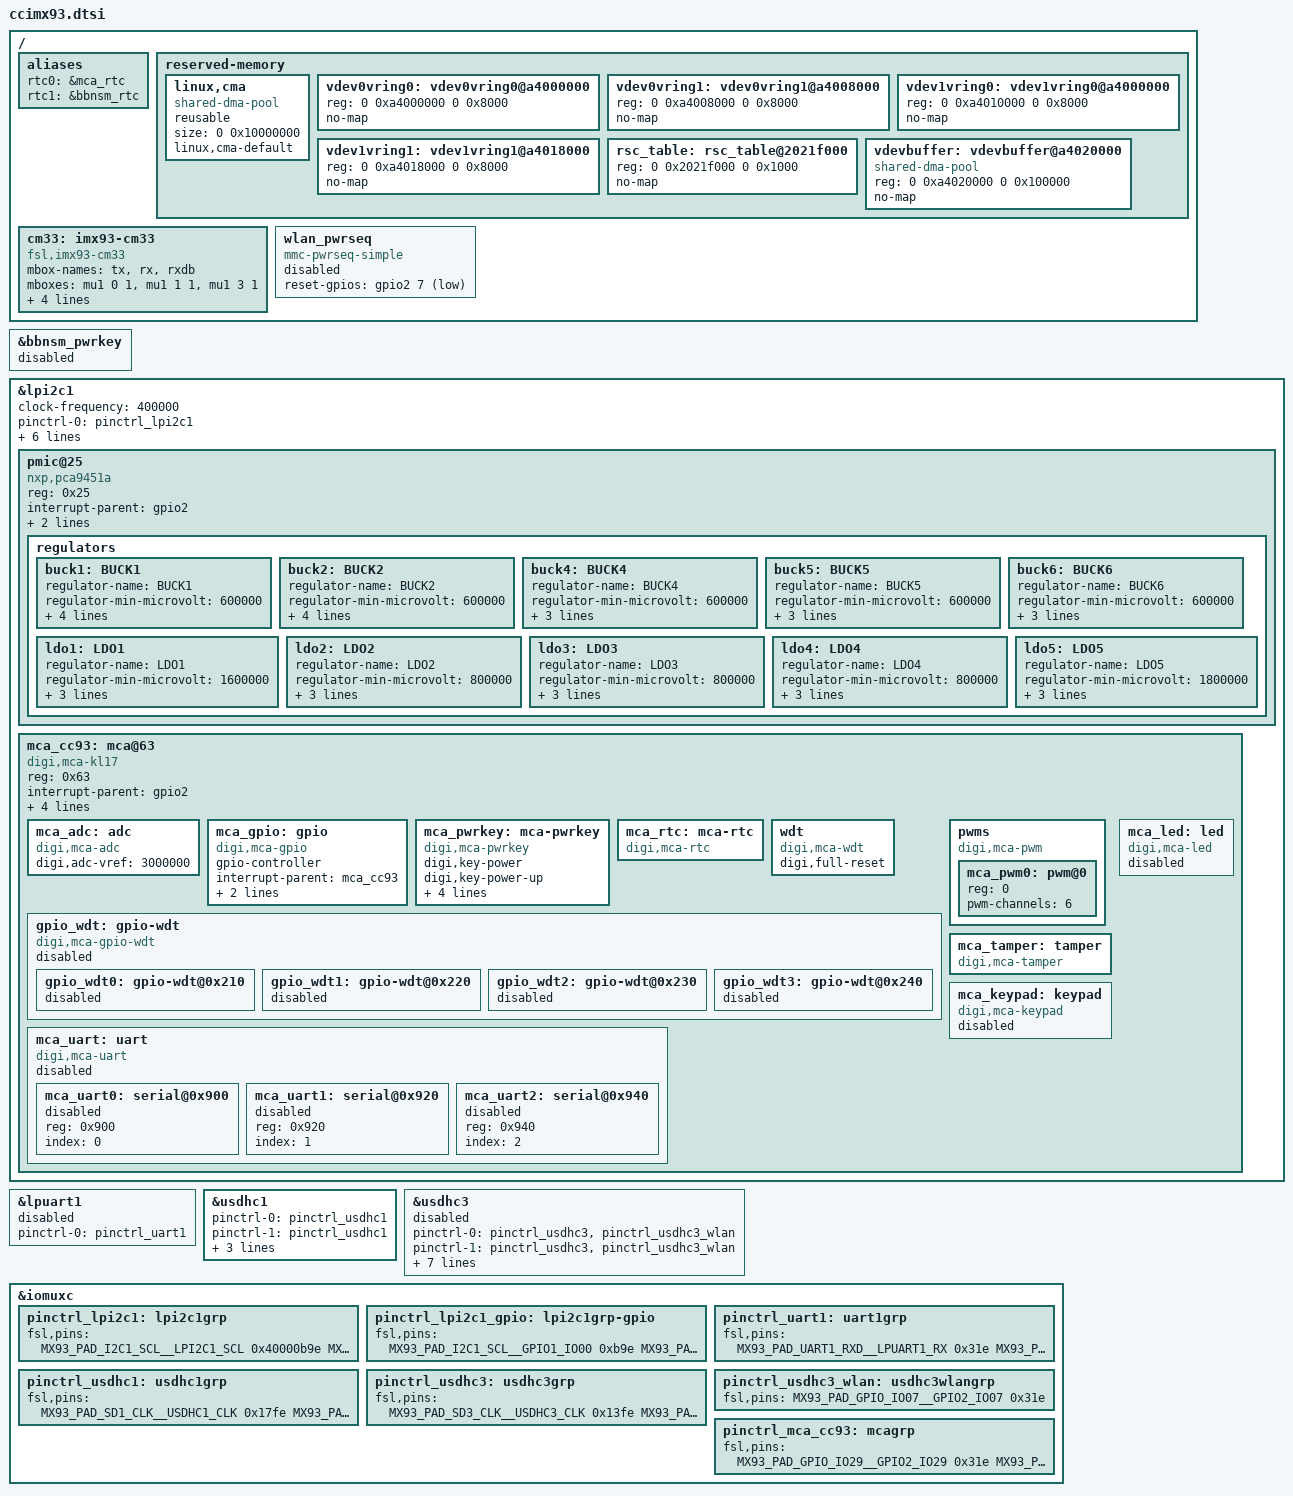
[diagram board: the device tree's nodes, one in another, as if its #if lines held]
/*
 * Copyright 2022, Digi International Inc.
 *
 * Permission to use, copy, modify, and/or distribute this software for any
 * purpose with or without fee is hereby granted, provided that the above
 * copyright notice and this permission notice appear in all copies.
 * THE SOFTWARE IS PROVIDED "AS IS" AND THE AUTHOR DISCLAIMS ALL WARRANTIES
 * WITH REGARD TO THIS SOFTWARE INCLUDING ALL IMPLIED WARRANTIES OF
 * MERCHANTABILITY AND FITNESS. IN NO EVENT SHALL THE AUTHOR BE LIABLE FOR
 * ANY SPECIAL, DIRECT, INDIRECT, OR CONSEQUENTIAL DAMAGES OR ANY DAMAGES
 * WHATSOEVER RESULTING FROM LOSS OF USE, DATA OR PROFITS, WHETHER IN AN
 * ACTION OF CONTRACT, NEGLIGENCE OR OTHER TORTIOUS ACTION, ARISING OUT OF
 * OR IN CONNECTION WITH THE USE OR PERFORMANCE OF THIS SOFTWARE.
 */

/ {
#if HAS_MCA
	aliases {
		rtc0 = &mca_rtc;
		rtc1 = &bbnsm_rtc;
	};
#endif

	reserved-memory {
		#address-cells = <2>;
		#size-cells = <2>;
		ranges;

		linux,cma {
			compatible = "shared-dma-pool";
			reusable;
			size = <0 0x10000000>;
			linux,cma-default;
		};

		vdev0vring0: vdev0vring0@a4000000 {
			reg = <0 0xa4000000 0 0x8000>;
			no-map;
		};

		vdev0vring1: vdev0vring1@a4008000 {
			reg = <0 0xa4008000 0 0x8000>;
			no-map;
		};

		vdev1vring0: vdev1vring0@a4000000 {
			reg = <0 0xa4010000 0 0x8000>;
			no-map;
		};

		vdev1vring1: vdev1vring1@a4018000 {
			reg = <0 0xa4018000 0 0x8000>;
			no-map;
		};

		rsc_table: rsc_table@2021f000 {
			reg = <0 0x2021f000 0 0x1000>;
			no-map;
		};

		vdevbuffer: vdevbuffer@a4020000 {
			compatible = "shared-dma-pool";
			reg = <0 0xa4020000 0 0x100000>;
			no-map;
		};
	};

	cm33: imx93-cm33 {
		compatible = "fsl,imx93-cm33";
		mbox-names = "tx", "rx", "rxdb";
		mboxes = <&mu1 0 1
			  &mu1 1 1
			  &mu1 3 1>;
		memory-region = <&vdevbuffer>, <&vdev0vring0>, <&vdev0vring1>,
				<&vdev1vring0>, <&vdev1vring1>, <&rsc_table>;
		fsl,startup-delay-ms = <500>;
	};

	wlan_pwrseq: wlan_pwrseq {
		compatible = "mmc-pwrseq-simple";
		/* Note that this is connected to the PDn line */

		reset-gpios = <&gpio2 7 GPIO_ACTIVE_LOW>;
		status = "disabled";
	};
};

#if HAS_MCA
/* Disable CPU power key */
&bbnsm_pwrkey {
	status = "disabled";
};
#endif

/* I2C bus conneccted to MCA and PMIC */
&lpi2c1 {
	#address-cells = <1>;
	#size-cells = <0>;
	clock-frequency = <400000>;
	pinctrl-names = "default", "gpio", "sleep";
	pinctrl-0 = <&pinctrl_lpi2c1>;
	pinctrl-1 = <&pinctrl_lpi2c1_gpio>;
	pinctrl-2 = <&pinctrl_lpi2c1>;
	scl-gpios = <&gpio1 0 GPIO_ACTIVE_HIGH>;
	sda-gpios = <&gpio1 1 GPIO_ACTIVE_HIGH>;
	digi,hold-time-ns = <8000>;
	digi,buffer-time-us = <35>;
	status = "okay";

	pmic@25 {
		compatible = "nxp,pca9451a";
		reg = <0x25>;

		interrupt-parent = <&gpio2>;
		interrupts = <29 IRQ_TYPE_LEVEL_LOW>;
		interrupt-flags = <0x00002088>;

		regulators {
			buck1: BUCK1 {
				regulator-name = "BUCK1";
				regulator-min-microvolt = <600000>;
				regulator-max-microvolt = <2187500>;
				regulator-boot-on;
				regulator-always-on;
				regulator-ramp-delay = <3125>;
			};

			buck2: BUCK2 {
				regulator-name = "BUCK2";
				regulator-min-microvolt = <600000>;
				regulator-max-microvolt = <2187500>;
				regulator-boot-on;
				regulator-always-on;
				regulator-ramp-delay = <3125>;
			};

			/* VDD_3V3 */
			buck4: BUCK4{
				regulator-name = "BUCK4";
				regulator-min-microvolt = <600000>;
				regulator-max-microvolt = <3400000>;
				regulator-boot-on;
				regulator-always-on;
			};

			/* VDD_1V8 */
			buck5: BUCK5{
				regulator-name = "BUCK5";
				regulator-min-microvolt = <600000>;
				regulator-max-microvolt = <3400000>;
				regulator-boot-on;
				regulator-always-on;
			};

			/* VDD2_DDR */
			buck6: BUCK6 {
				regulator-name = "BUCK6";
				regulator-min-microvolt = <600000>;
				regulator-max-microvolt = <3400000>;
				regulator-boot-on;
				regulator-always-on;
			};

			/* NVCC_BBSM_1V8 */
			ldo1: LDO1 {
				regulator-name = "LDO1";
				regulator-min-microvolt = <1600000>;
				regulator-max-microvolt = <3300000>;
				regulator-boot-on;
				regulator-always-on;
			};

			/* LDO2 */
			ldo2: LDO2 {
				regulator-name = "LDO2";
				regulator-min-microvolt = <800000>;
				regulator-max-microvolt = <1150000>;
				regulator-boot-on;
				regulator-always-on;
			};

			/* LDO3 */
			ldo3: LDO3 {
				regulator-name = "LDO3";
				regulator-min-microvolt = <800000>;
				regulator-max-microvolt = <3300000>;
				regulator-boot-on;
				regulator-always-on;
			};

			/* VDD_ANA_0V8 */
			ldo4: LDO4 {
				regulator-name = "LDO4";
				regulator-min-microvolt = <800000>;
				regulator-max-microvolt = <3300000>;
				regulator-boot-on;
				regulator-always-on;
			};

			/* MUX_3V3_1V8 */
			ldo5: LDO5 {
				regulator-name = "LDO5";
				regulator-min-microvolt = <1800000>;
				regulator-max-microvolt = <3300000>;
				regulator-boot-on;
				regulator-always-on;
			};
		};
	};

#if HAS_MCA
	mca_cc93: mca@63 {
		compatible = "digi,mca-kl17";
		reg = <0x63>;
		interrupt-parent = <&gpio2>;
		interrupts = <29 IRQ_TYPE_LEVEL_LOW>;
		interrupt-controller;
		#interrupt-cells = <2>;
		fw-update-gpio = <&gpio2 28 GPIO_ACTIVE_LOW>;
		pinctrl-names = "default";
		pinctrl-0 = <&pinctrl_mca_cc93>;

		mca_adc: adc {
			compatible = "digi,mca-adc";
			digi,adc-vref = <3000000>;
		};

		mca_gpio: gpio {
			compatible = "digi,mca-gpio";
			gpio-controller;
			#gpio-cells = <2>;

			interrupt-parent = <&mca_cc93>;
			interrupt-controller;
			#interrupt-cells = <2>;

			/* Disable all mca GPIOs as power off wake up sources */
			pwroff-wakeup-capable-ios = <>;
		};

		mca_pwrkey: mca-pwrkey {
			compatible = "digi,mca-pwrkey";
			digi,key-power;
			digi,key-power-up;
			digi,key-sleep;
			digi,debounce-ms = <100>;
			digi,pwroff-delay-sec = <6>;
			digi,pwroff-guard-sec = <30>;
		};

		mca_rtc: mca-rtc {
			compatible = "digi,mca-rtc";
		};

		wdt {
			compatible = "digi,mca-wdt";
			digi,full-reset;
		};

		gpio_wdt: gpio-wdt {
			compatible = "digi,mca-gpio-wdt";
			status = "disabled";

			gpio_wdt0: gpio-wdt@0x210 {
				status = "disabled";
			};

			gpio_wdt1: gpio-wdt@0x220 {
				status = "disabled";
			};

			gpio_wdt2: gpio-wdt@0x230 {
				status = "disabled";
			};

			gpio_wdt3: gpio-wdt@0x240 {
				status = "disabled";
			};
		};

		pwms {
			compatible = "digi,mca-pwm";
			#address-cells = <1>;
			#size-cells = <0>;

			mca_pwm0: pwm@0 {
				reg = <0>;
				pwm-channels = <6>;
				#pwm-cells = <3>;
			};
		};

		mca_tamper: tamper {
			compatible = "digi,mca-tamper";
		};

		mca_uart: uart {
			compatible = "digi,mca-uart";
			#address-cells = <1>;
			#size-cells = <0>;
			status = "disabled";

			mca_uart0: serial@0x900 {
				reg = <0x900>;
				index = <0>;
				status = "disabled";
			};

			mca_uart1: serial@0x920 {
				reg = <0x920>;
				index = <1>;
				status = "disabled";
			};

			mca_uart2: serial@0x940 {
				reg = <0x940>;
				index = <2>;
				status = "disabled";
			};
		};

		mca_keypad: keypad {
			compatible = "digi,mca-keypad";
			status = "disabled";
		};

		mca_led: led {
			compatible = "digi,mca-led";
			status = "disabled";
		};
	};
#endif
};

/* Bluetooth UART */
&lpuart1 {
	pinctrl-names = "default";
	pinctrl-0 = <&pinctrl_uart1>;
	status = "disabled";
};

/* eMMC */
&usdhc1 {
	pinctrl-names = "default", "state_100mhz", "state_200mhz";
	pinctrl-0 = <&pinctrl_usdhc1>;
	pinctrl-1 = <&pinctrl_usdhc1>;
	pinctrl-2 = <&pinctrl_usdhc1>;
	bus-width = <8>;
	non-removable;
	status = "okay";
};

/* Wifi MAC */
&usdhc3 {
	pinctrl-names = "default", "state_100mhz", "state_200mhz";
	pinctrl-0 = <&pinctrl_usdhc3>, <&pinctrl_usdhc3_wlan>;
	pinctrl-1 = <&pinctrl_usdhc3>, <&pinctrl_usdhc3_wlan>;
	pinctrl-2 = <&pinctrl_usdhc3>, <&pinctrl_usdhc3_wlan>;

	mmc-pwrseq = <&wlan_pwrseq>;
	bus-width = <4>;
	keep-power-in-suspend;
	non-removable;
	wakeup-source;
	fsl,sdio-async-interrupt-enabled;
	status = "disabled";

	// TODO enable when IO is defined
	//wifi_wake_host {
	//	compatible = "nxp,wifi-wake-host";
	//	interrupt-parent = <&gpio3>;
	//	interrupts = <26 IRQ_TYPE_LEVEL_LOW>;
	//	interrupt-names = "host-wake";
	//};
};

/* IOMUX */
&iomuxc {
	/* Internal I2C (MCA, PMIC) */
	pinctrl_lpi2c1: lpi2c1grp {
		fsl,pins = <
			MX93_PAD_I2C1_SCL__LPI2C1_SCL			0x40000b9e
			MX93_PAD_I2C1_SDA__LPI2C1_SDA			0x40000b9e
		>;
	};

	pinctrl_lpi2c1_gpio: lpi2c1grp-gpio {
		fsl,pins = <
			MX93_PAD_I2C1_SCL__GPIO1_IO00			0xb9e
			MX93_PAD_I2C1_SDA__GPIO1_IO01			0xb9e
		>;
	};

	/* Bluetooth UART */
	pinctrl_uart1: uart1grp {
		fsl,pins = <
			MX93_PAD_UART1_RXD__LPUART1_RX			0x31e
			MX93_PAD_UART1_TXD__LPUART1_TX			0x31e
			MX93_PAD_UART2_RXD__LPUART1_CTS_B		0x31e
			MX93_PAD_UART2_TXD__LPUART1_RTS_B		0x31e
		>;
	};

	/* eMMC */
	pinctrl_usdhc1: usdhc1grp {
		fsl,pins = <
			MX93_PAD_SD1_CLK__USDHC1_CLK			0x17fe
			MX93_PAD_SD1_CMD__USDHC1_CMD			0x13fe
			MX93_PAD_SD1_DATA0__USDHC1_DATA0		0x13fe
			MX93_PAD_SD1_DATA1__USDHC1_DATA1		0x13fe
			MX93_PAD_SD1_DATA2__USDHC1_DATA2		0x13fe
			MX93_PAD_SD1_DATA3__USDHC1_DATA3		0x13fe
			MX93_PAD_SD1_DATA4__USDHC1_DATA4		0x13fe
			MX93_PAD_SD1_DATA5__USDHC1_DATA5		0x13fe
			MX93_PAD_SD1_DATA6__USDHC1_DATA6		0x13fe
			MX93_PAD_SD1_DATA7__USDHC1_DATA7		0x13fe
			MX93_PAD_SD1_STROBE__USDHC1_STROBE		0x17fe
		>;
	};

	/* Wifi MAC */
	pinctrl_usdhc3: usdhc3grp {
		fsl,pins = <
			MX93_PAD_SD3_CLK__USDHC3_CLK			0x13fe
			MX93_PAD_SD3_CMD__USDHC3_CMD			0x13fe
			MX93_PAD_SD3_DATA0__USDHC3_DATA0		0x13fe
			MX93_PAD_SD3_DATA1__USDHC3_DATA1        	0x13fe
			MX93_PAD_SD3_DATA2__USDHC3_DATA2        	0x13fe
			MX93_PAD_SD3_DATA3__USDHC3_DATA3        	0x13fe
		>;
	};

	/* Wifi/BT control lines */
	pinctrl_usdhc3_wlan: usdhc3wlangrp {
		fsl,pins = <
			/* WLAN_PDn */
			MX93_PAD_GPIO_IO07__GPIO2_IO07			0x31e
		>;
	};

	/* MCA pinctrl */
	pinctrl_mca_cc93: mcagrp {
		fsl,pins = <
			/* MCA_nINT */
			MX93_PAD_GPIO_IO29__GPIO2_IO29			0x31e
			/* MCA_FW_UPDATE */
			MX93_PAD_GPIO_IO28__GPIO2_IO28			0x31e
		>;
	};
};
